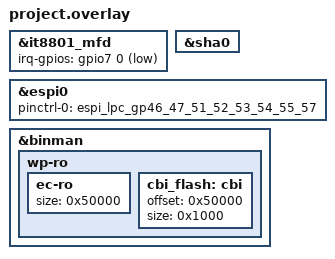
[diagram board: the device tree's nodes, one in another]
/* Copyright 2025 The ChromiumOS Authors
 * Use of this source code is governed by a BSD-style license that can be
 * found in the LICENSE file.
 */

/* ocelot program common DTS includes */

#include <cros/integrated_fwid.dtsi>
#include <cros/cbi_flash.dtsi>

/* ocelotrvp-npcx project DTS includes */
#include "board.dtsi"
#include "psl.dtsi"
#include <ite/it8801-common-cfg.dtsi>

&it8801_mfd {
	irq-gpios = <&gpio7 0 GPIO_ACTIVE_LOW>;
};

&sha0 {
	status = "okay";
};

&espi0 {
	status = "okay";
	pinctrl-0 = <&espi_lpc_gp46_47_51_52_53_54_55_57>;
	pinctrl-names = "default";
};

/* Required for flashing */
&binman {
	wp-ro {
		ec-ro {
			size = <0x50000>;
		};
		cbi_flash: cbi {
			/*
			 * CBI section size is 0x1000 bytes, the
			 * CBI portion lies at the end of EC_RO section.
			 * EC_RO section ends at 0x50000 byte which
			 * is the offset.
			 */
			offset = <0x50000>;
			size = <0x1000>;
		};
	};
};
